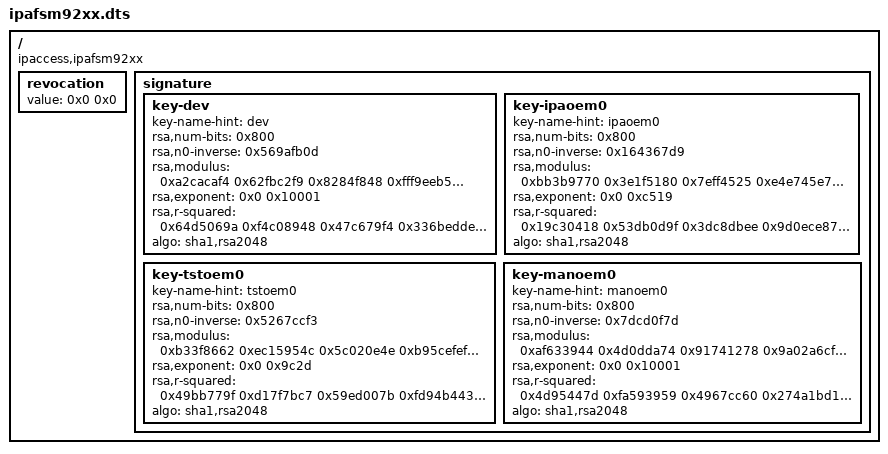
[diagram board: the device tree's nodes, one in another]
/dts-v1/;

/include/ "skeleton.dtsi"

/ {
    compatible = "ipaccess,ipafsm92xx";

    revocation {
        value = <0x0 0x0>;
    };

    signature {
        key-dev {
            key-name-hint = "dev";
            rsa,num-bits = <0x800>;
            rsa,n0-inverse = <0x569afb0d>;
            rsa,modulus = <0xa2cacaf4 0x62fbc2f9 0x8284f848 0xfff9eeb5 0x43b196bc 0x9e0689ed 0x9d5e00ab 0x5981993e 0x67a3b142 0x6694e452 0xa64b0723 0xa53a83c5 0x797a7762 0x87a1796f 0x1deb586f 0xa4a0d6c 0xadbed894 0xdfd7f1e2 0xd94413c4 0xa3eccc69 0x47984871 0x405b09ec 0xc702542a 0x2b80dede 0x3960563 0xdcfd9a3f 0xc507984c 0xadc98117 0xfc2d9f59 0x9cf8b640 0x5505d59 0x483defb5 0xf1e00cd5 0x90638e71 0x8cedb330 0x837792ec 0x7252bc30 0xda6c0863 0xc4151126 0x25756646 0xd429da0b 0xfff6e1e1 0x5afb3b3c 0x36d14466 0xa07aead7 0x4c7914e2 0x6e6dda7d 0x3643411f 0x9d2b61dc 0x494893db 0xfcc169a0 0x90f5d89e 0xd7801f72 0xef9d68eb 0x325119c 0x22b6770d 0x3e0dbb77 0x93f3020f 0x41aaecf8 0x793b6831 0x599011c1 0x3e5c91c4 0x5dcb0932 0xcc0fb43b>;
            rsa,exponent = <0x0 0x10001>;
            rsa,r-squared = <0x64d5069a 0xf4c08948 0x47c679f4 0x336bedde 0xab2a80f8 0xba8d3f77 0xbc115a35 0x8f6667ee 0xe709b5b1 0x44996359 0x7733d789 0x71b90f28 0xe1f08158 0x47c283e8 0xf64af5a6 0x143ef0f5 0x3af84a32 0x4afb4126 0xccf365e0 0xd2908d5b 0xe58c7350 0x5c3357c1 0x5631cf29 0x712d324d 0x7115eb18 0xd44b8e8 0x799fc0dd 0x13b08e3c 0xfe69be90 0xbbd5f32b 0xa3d82f3d 0x68e5c521 0x4a7dde89 0x925a2329 0x43e47746 0x6ee98b9b 0x67a535d1 0x7cf34c97 0x67811736 0x63910a87 0xad0ade7e 0x19f7afff 0x533dd1f8 0x94b25a47 0x9ca7df8c 0xabbd1aec 0x19a1ddd2 0x9a560c4 0xe931d908 0x55050835 0xd7ccbc75 0xfb49a73e 0x9847963f 0x1c0d2e0 0xeb2e711b 0xa2698957 0xc96b5b0a 0xd8264b1f 0x9a5a4858 0xedd9ac27 0xe5a77196 0x7db3d1af 0x3d802b85 0xfbdcbb83>;
            algo = "sha1,rsa2048";
        };
        key-ipaoem0 {
            key-name-hint = "ipaoem0";
            rsa,num-bits = <0x800>;
            rsa,n0-inverse = <0x164367d9>;
            rsa,modulus = <0xbb3b9770 0x3e1f5180 0x7eff4525 0xe4e745e7 0xac424536 0x26781e6b 0xc6ca0264 0x5d1cb9b4 0x31003c24 0x97b0328e 0x6781a479 0x48743780 0xa2710574 0x94aa1680 0x66bc765d 0xdd6161fe 0x63f83220 0x84411772 0xb13e7929 0xa1d94e2d 0xe68e0f7b 0x4839f5c9 0x7611507c 0x144d5d49 0x3def00f9 0x3ad40fa1 0xffa612db 0x2a5ed970 0x2d99374a 0x44cf07b8 0x11b73747 0xd567b682 0x7780242a 0xbc598e23 0xe302ba9b 0x4e0100c6 0xae796b87 0xeb74e20 0x6c5393a1 0x5dfadd86 0x10d2b40c 0x4b03576b 0xc90841a8 0xbf10b56d 0xf1b94bd4 0xd43086b8 0xc3446e53 0xbfd1e455 0x9f163d53 0x903b1e98 0x37b245db 0x5e9711f1 0x73c685aa 0x95b72631 0xbea4e174 0x376f67e3 0xc495989b 0x28c74975 0x3fac1eec 0x37450a69 0x98cc6c76 0x42d64cea 0xcd7a3ca5 0x58ab5797>;
            rsa,exponent = <0x0 0xc519>;
            rsa,r-squared = <0x19c30418 0x53db0d9f 0x3dc8dbee 0x9d0ece87 0x29e1f44d 0xad819afb 0x902c1500 0xd39f4c8f 0xf01bd7df 0xbcfcaadb 0x4d24794f 0x4cb4f3ba 0x7698472a 0x6c06b61a 0xd61b256b 0xca7104a3 0x3105edc6 0x48230857 0xf3eb8b00 0xa0c5b8dc 0xffbcb731 0x61d79594 0x4501aa47 0x248441e2 0x27022579 0xb32379fa 0xcd24db4 0xe23676a5 0xab41a351 0x20b535d2 0x79ef6d5d 0x37035e80 0x24b33277 0x108cb381 0xc7b4aa01 0x9afbcf26 0x28e7cb8f 0x3604653 0xf5d84771 0xa6b7fa6e 0xdbb60f5e 0xbb9ed320 0x71862eac 0xedf56985 0x1c41037 0x5980fcb 0x365c7623 0x116799b 0xefa2c50 0xb22ab057 0xf820fe5 0xebf52abf 0xb5162250 0x118394de 0x67bbefd2 0xcf8be027 0x3e71c9be 0x3356ce2b 0x7369700a 0x3bf9bb6e 0x16d58614 0x4bbcdf41 0x22ad04c 0xb6c3edc8>;
            algo = "sha1,rsa2048";
        };
        key-tstoem0 {
            key-name-hint = "tstoem0";
            rsa,num-bits = <0x800>;
            rsa,n0-inverse = <0x5267ccf3>;
            rsa,modulus = <0xb33f8662 0xec15954c 0x5c020e4e 0xb95cefef 0xa92233df 0x41a95dcf 0x6c07d326 0xa7415afd 0x84c7a937 0x3fdfafe2 0x2627ecb 0x35fe99af 0xd56f0579 0x41b10951 0x4b65525a 0x80a8bdae 0x6a85d1b0 0x6b9f07 0x44542520 0xe4f0b1cc 0x3d8fcf76 0x7cf83dc2 0xf186198b 0xd403cbae 0xd236bd5f 0xbfda991e 0xfffdbc06 0xba39cda5 0xbd3f4b19 0x50edcf6e 0xa8c33a60 0xd74132eb 0x1a89b9cc 0xd7e402ba 0x46590e0e 0x3d286b4a 0x7cb54d6d 0xf24e9ff8 0x4a04ba36 0xca649aba 0xefc7d816 0xe0e9346f 0x7be55b91 0x17315225 0xd67c8b5d 0xdc1dcc84 0x48f322a1 0xa52dc73 0x5e7ddac2 0x880c2093 0xb56f7f13 0xd2f520e3 0x9343deaa 0x4efb62c6 0xe5852a 0x15c24dec 0x2346a677 0xafa169b0 0x958643c0 0x3c96d55f 0x107de770 0x7af7e97 0xcb55345f 0xa7c1d3c5>;
            rsa,exponent = <0x0 0x9c2d>;
            rsa,r-squared = <0x49bb779f 0xd17f7bc7 0x59ed007b 0xfd94b443 0x4ab70e47 0x9f74cd33 0xc264f8dd 0x72c3d14d 0x8f3a993e 0x1fd5a763 0xdebc135e 0xc7b6c884 0x34bc3701 0x1b27c749 0x49396be4 0x77918187 0x484dde52 0x25158c07 0x3ba329c0 0xbe9829ff 0x231d5831 0xa8d2bb3f 0x44f862e9 0xf2f91087 0xa77c1712 0x4044eea6 0xf4424c60 0xc98747f5 0x286b696a 0x54e2a31b 0x5116041c 0x2fb36f4 0xb74200c4 0xcf286598 0xbb4d869b 0xd2de2599 0x1690c9ce 0x28b669fd 0x8bbd35ca 0x3faf640f 0xbda99944 0x81fb9959 0x949bb12e 0xf4d861af 0x7e652529 0xdf3e4526 0xd903fd4c 0xc5a1b1c8 0x24b8728c 0x2367bf19 0xbe817cb9 0xdabd7431 0x3f57a7d6 0x74f8e954 0xf35dc699 0x117122b5 0x655be7e9 0x7dbc0bd7 0xcc80c38 0x7c4a577e 0x43e01b78 0x68686652 0x558be3ee 0xae650c05>;
            algo = "sha1,rsa2048";
        };
        key-manoem0 {
            key-name-hint = "manoem0";
            rsa,num-bits = <0x800>;
            rsa,n0-inverse = <0x7dcd0f7d>;
            rsa,modulus = <0xaf633944 0x4d0dda74 0x91741278 0x9a02a6cf 0x9e420c7c 0xe13888aa 0x2aeda6b8 0xdc37d538 0x76fb884e 0x9d918019 0x17a06957 0x308b6759 0xc3035d4c 0xe157dbb4 0x60a55f00 0x93dfd332 0xbc64e7f3 0x2e9024c8 0xfd283c9f 0x26a6ad97 0xfa8ef913 0xc2bf9429 0x6eeec489 0xb5e545b5 0x4ae578ea 0xe6c86515 0x46483db2 0x299b606a 0x19735a3c 0xf3dd986 0x31eca97b 0x3328439e 0xdb1b68e5 0xdbf49aa6 0x943d3f23 0x928314d4 0x61297d48 0xa4fd7096 0x2e9b8dac 0xb9e41b55 0x58787948 0x917c52ed 0xcb16de96 0xb4e18c54 0xcb382479 0x214f3375 0x9ff5404d 0x6bbc1761 0x13f0c2be 0x7ca9eec2 0x810e8c4f 0x34bad87a 0x7a77fee4 0xca500be3 0xfdaa2f44 0x6ffe87d0 0x1db27f9 0x320f131e 0x8fe0bb2a 0x1ea74fad 0x3edbf9b4 0x5b6551da 0xbf3b8a98 0x61a0de2b>;
            rsa,exponent = <0x0 0x10001>;
            rsa,r-squared = <0x4d95447d 0xfa593959 0x4967cc60 0x274a1bd1 0xbf3e22c8 0x45ea6395 0xb58359b4 0xa9e5f193 0xcfa50c3a 0x6b741e1f 0x37ff98e7 0xbb351f54 0x11363876 0xa81f59b5 0x3f5e4482 0xcf45e3b2 0xfe58b52 0xe6fd93c1 0x2cd4d8cd 0x231ab543 0x3bff3d0a 0xfb78938d 0xbd0a79b 0x85231d57 0x8f21ff75 0xf7d7c878 0xa40e251b 0x3468a8ec 0x6775bf3c 0xc4a0262f 0xc78d6e16 0xfe7d784f 0xf9166f06 0x8bd5372a 0x4f151f6 0x4094c03d 0x1d6eebb0 0x8e508876 0xf0462747 0x4c2c5703 0xba613102 0xe6d55b23 0xab00b42b 0x951435ab 0x337937 0xb757a4cb 0x607f9d17 0x97ddbe36 0x353f1b07 0x8502c361 0xdbb70e57 0x8ad9fa57 0x3adb1478 0x5416f394 0xc0af4ccd 0x47299d6d 0xfd892f61 0x44baaef3 0xf70f96ae 0x8e6c5af 0x803848a 0x2711bad 0x62bcc80a 0x5f79be58>;
            algo = "sha1,rsa2048";
        };
    };
};
